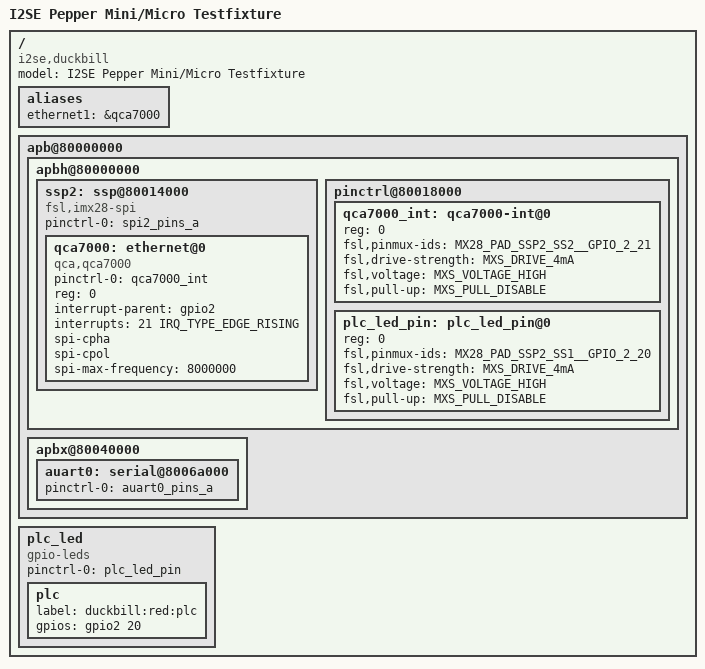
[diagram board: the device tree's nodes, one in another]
/*
 * Copyright (C) 2017 I2SE GmbH <info@i2se.com>
 *
 * The code contained herein is licensed under the GNU General Public
 * License. You may obtain a copy of the GNU General Public License
 * Version 2 or later at the following locations:
 *
 * http://www.opensource.org/licenses/gpl-license.html
 * http://www.gnu.org/copyleft/gpl.html
 */

/dts-v1/;
#include <dt-bindings/interrupt-controller/irq.h>
#include "imx28-duckbill-2-common.dtsi"

/ {
	model = "I2SE Pepper Mini/Micro Testfixture";
	compatible = "i2se,duckbill", "fsl,imx28";

	aliases {
		ethernet1 = &qca7000;
	};

	apb@80000000 {
		apbh@80000000 {
			ssp2: ssp@80014000 {
				compatible = "fsl,imx28-spi";
				pinctrl-names = "default";
				pinctrl-0 = <&spi2_pins_a>;
				status = "okay";

				qca7000: ethernet@0 {
					compatible = "qca,qca7000";
					pinctrl-names = "default";
					pinctrl-0 = <&qca7000_int>;
					reg = <0>;
					interrupt-parent = <&gpio2>;
					interrupts = <21 IRQ_TYPE_EDGE_RISING>;
					spi-cpha;
					spi-cpol;
					spi-max-frequency = <8000000>;
				};
			};

			pinctrl@80018000 {
				qca7000_int: qca7000-int@0 {
					reg = <0>;
					fsl,pinmux-ids = <
						MX28_PAD_SSP2_SS2__GPIO_2_21
					>;
					fsl,drive-strength = <MXS_DRIVE_4mA>;
					fsl,voltage = <MXS_VOLTAGE_HIGH>;
					fsl,pull-up = <MXS_PULL_DISABLE>;
				};

				plc_led_pin: plc_led_pin@0 {
					reg = <0>;
					fsl,pinmux-ids = <
						MX28_PAD_SSP2_SS1__GPIO_2_20
					>;
					fsl,drive-strength = <MXS_DRIVE_4mA>;
					fsl,voltage = <MXS_VOLTAGE_HIGH>;
					fsl,pull-up = <MXS_PULL_DISABLE>;
				};
			};
		};

		apbx@80040000 {
			auart0: serial@8006a000 {
				pinctrl-names = "default";
				pinctrl-0 = <&auart0_pins_a>;
				status = "okay";
			};
		};
	};

	plc_led {
		compatible = "gpio-leds";
		pinctrl-names = "default";
		pinctrl-0 = <&plc_led_pin>;

		plc {
			label = "duckbill:red:plc";
			gpios = <&gpio2 20 GPIO_ACTIVE_HIGH>;
		};
	};
};
